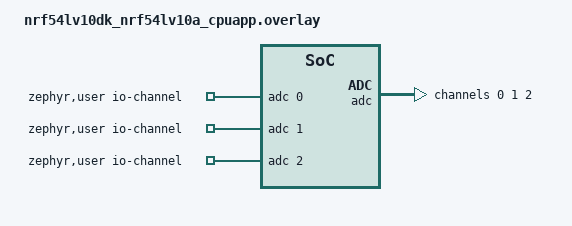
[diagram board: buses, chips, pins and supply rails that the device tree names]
/*
 * Copyright (c) 2026 Nordic Semiconductor ASA
 *
 * SPDX-License-Identifier: Apache-2.0
 */

/ {
	zephyr,user {
		io-channels = <&adc 0>, <&adc 1>, <&adc 2>;
	};
};

&adc {
	#address-cells = <1>;
	#size-cells = <0>;
	status = "okay";

	channel@0 {
		reg = <0>;
		zephyr,gain = "ADC_GAIN_1";
		zephyr,reference = "ADC_REF_INTERNAL";
		zephyr,acquisition-time = <ADC_ACQ_TIME(ADC_ACQ_TIME_MICROSECONDS, 10)>;
		zephyr,input-positive = <NRF_SAADC_AIN0>; /* P1.00 */
		zephyr,resolution = <10>;
	};

	channel@1 {
		reg = <1>;
		zephyr,gain = "ADC_GAIN_1";
		zephyr,reference = "ADC_REF_EXTERNAL0";
		zephyr,acquisition-time = <ADC_ACQ_TIME_DEFAULT>;
		zephyr,input-positive = <NRF_SAADC_AIN1>; /* P1.01 */
		zephyr,resolution = <12>;
	};

	channel@2 {
		reg = <2>;
		zephyr,gain = "ADC_GAIN_1";
		zephyr,reference = "ADC_REF_INTERNAL";
		zephyr,acquisition-time = <ADC_ACQ_TIME(ADC_ACQ_TIME_MICROSECONDS, 10)>;
		zephyr,input-positive = <NRF_SAADC_AIN7>; /* P1.12 */
		zephyr,resolution = <10>;
	};
};
